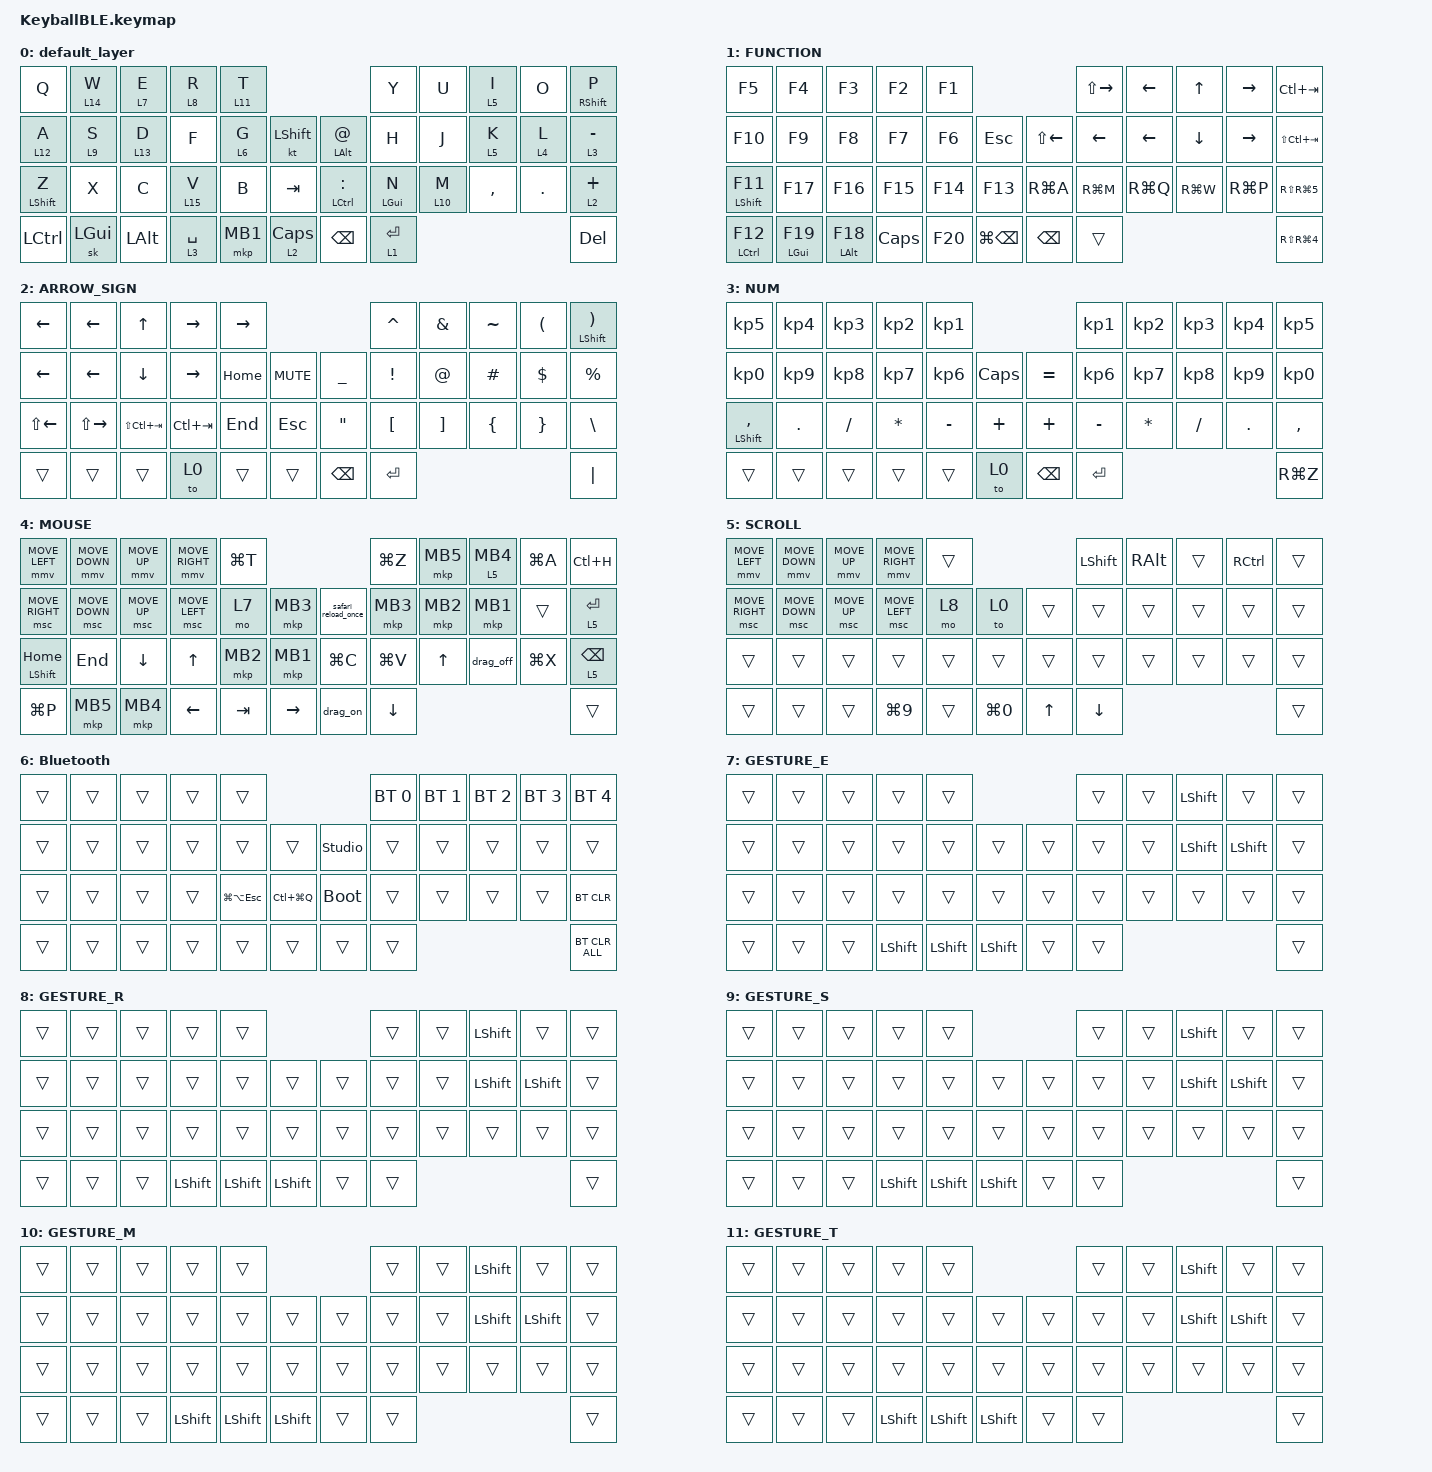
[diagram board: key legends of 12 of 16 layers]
/* ===============================
 * KeyballBLE.keymap（全置き換え / 整理版）
 *  - レイヤー順＝番号（0起算）
 *    0 default_layer
 *    1 FUNCTION
 *    2 ARROW_SIGN
 *    3 NUM
 *    4 MOUSE
 *    5 SCROLL
 *    6 Bluetooth
 *    7 GESTURE_E
 *    8 GESTURE_R
 *    9 GESTURE_S
 *   10 GESTURE_M
 *   11 GESTURE_T
 *   12 GESTURE_A
 *   13 GESTURE_D
 *   14 GESTURE_W
 *   15 SCROLL_SNAP
 *   16 SNIPE（キーで遅いスクロール：MOVE_X/Y(8)）
 *  - overlay 側で gesture を 7/8/9/10/11/12/13/14 に紐付け
 *  - mm_l*_dir は overlay の zip_mouse_gesture_* から呼ばれる
 * =============================== */

#define ZMK_POINTING_DEFAULT_SCRL_VAL 80

#include "dts/mouse-gesture.local.dtsi"
#include <dt-bindings/zmk/mouse.h>
#include <behaviors.dtsi>
#include <dt-bindings/zmk/bt.h>
#include <dt-bindings/zmk/keys.h>
#include <dt-bindings/zmk/pointing.h>

&msc {
    time-to-max-speed-ms = <0>;
    acceleration-exponent = <0>;
};

&mt {
    flavor = "balanced";
    quick-tap-ms = <0>;
};

&mouse_gesture_kp {
    tapping-term-ms = <200>;
    quick-tap-ms = <0>;
    flavor = "tap-preferred";
};

&mouse_gesture_mkp {
    tapping-term-ms = <200>;
    quick-tap-ms = <0>;
    flavor = "tap-preferred";
};

/ {
    combos {
        compatible = "zmk,combos";

        mb2_combo {
            bindings = <&mkp MB2>;
            key-positions = <19 18>;
        };

        scroll_combos {
            bindings = <&tog 5>;
            key-positions = <7 8>;
        };

        drag_off_combo {
            bindings = <&drag_off>;
            key-positions = <31 32>;
        };

        key1 {
            bindings = <&kp EXCLAMATION>;
            key-positions = <17 18>;
        };

        key2 {
            bindings = <&kp QUESTION>;
            key-positions = <29 30>;
        };

        scrl_up {
            bindings = <&msc MOVE_UP>;
            key-positions = <21 33>;
        };

        scrl_down {
            bindings = <&msc MOVE_DOWN>;
            key-positions = <33 42>;
        };

        left_shift {
            bindings = <&kp LEFT_SHIFT>;
            key-positions = <0 1>;
        };

        right_shift {
            bindings = <&kp LEFT_SHIFT>;
            key-positions = <8 9>;
        };

        tab {
            bindings = <&kp TAB>;
            key-positions = <11 12>;
        };

        lstab {
            bindings = <&kp LS(TAB)>;
            key-positions = <1 2>;
        };

        click {
            bindings = <&mkp MB1>;
            key-positions = <19 20>;
        };
    };

    macros {
        safari_reload_once: safari_reload_once {
            compatible = "zmk,behavior-macro";
            label = "SAFARI_RELOAD_ONCE";
            #binding-cells = <0>;
            bindings =
                <&macro_press>,
                <&kp LGUI>,
                <&macro_tap>,
                <&kp R>,
                <&macro_release>,
                <&kp LGUI>;
        };

        to_layer_0: to_layer_0 {
            compatible = "zmk,behavior-macro-one-param";
            label = "TO_LAYER_0";
            #binding-cells = <1>;
            bindings = <&to 0 &macro_param_1to1 &kp MACRO_PLACEHOLDER>;
        };

        drag_on: drag_on {
            compatible = "zmk,behavior-macro";
            label = "DRAG_ON";
            #binding-cells = <0>;
            bindings = <&macro_press>, <&mkp MB1>;
        };

        drag_off: drag_off {
            compatible = "zmk,behavior-macro";
            label = "DRAG_OFF";
            #binding-cells = <0>;
            bindings = <&macro_release>, <&mkp MB1>;
        };

        lm: lm {
            compatible = "zmk,behavior-macro-two-param";
            #binding-cells = <2>;
            wait-ms = <0>;
            tap-ms = <0>;
            bindings =
                <&macro_param_1to1>,
                <&macro_press>,
                <&mo MACRO_PLACEHOLDER &macro_param_2to1>,
                <&macro_press>,
                <&kp MACRO_PLACEHOLDER>,
                <&macro_pause_for_release>,
                <&macro_param_2to1>,
                <&macro_release>,
                <&kp MACRO_PLACEHOLDER &macro_param_1to1>,
                <&macro_release>,
                <&mo MACRO_PLACEHOLDER>;
        };
    };

    behaviors {
        gesture_mo_kp: gesture_mo_kp {
            compatible = "zmk,behavior-hold-tap";
            label = "GESTURE_MO_KP";
            bindings = <&mo>, <&kp>;

            #binding-cells = <2>;

            /* タップ優先（キー入力寄り） */

            flavor = "tap-preferred";
            tapping-term-ms = <210>;
            quick-tap-ms = <150>;
            require-prior-idle-ms = <450>;
        };

        lt_to_layer_0: lt_to_layer_0 {
            compatible = "zmk,behavior-hold-tap";
            label = "LAYER_TAP_TO_0";
            bindings = <&mo>, <&to_layer_0>;

            #binding-cells = <2>;
            tapping-term-ms = <210>;
            flavor = "tap-preferred";
            quick-tap-ms = <150>;
            require-prior-idle-ms = <350>;
        };

        rotate: rotate {
            compatible = "zmk,behavior-sensor-rotate";
            label = "ROTATE";
            #sensor-binding-cells = <0>;
            bindings = <&msc MOVE_UP>, <&msc MOVE_DOWN>;

            tap-ms = <20>;
        };

        lt_mkp: lt_mkp {
            compatible = "zmk,behavior-hold-tap";
            label = "LT_MKP";
            bindings = <&mo>, <&mkp>;

            #binding-cells = <2>;
            tapping-term-ms = <200>;
        };

        mod_mkp: mod_mkp {
            compatible = "zmk,behavior-hold-tap";
            label = "MOD_MKP";
            bindings = <&kp>, <&mkp>;

            #binding-cells = <2>;
            tapping-term-ms = <200>;
        };

        dragkey: dragkey {
            compatible = "zmk,behavior-hold-tap";
            label = "DRAGKEY";
            bindings = <&drag_on>, <&mkp>;

            #binding-cells = <2>;
            tapping-term-ms = <200>;
            require-prior-idle-ms = <150>;
            flavor = "tap-preferred";
            quick-tap-ms = <100>;
        };

        g_shft: g_shft {
            compatible = "zmk,behavior-sticky-key";
            #binding-cells = <1>;
            release-after-ms = <1000>;
            bindings = <&kp>;
        };

        mm_l1_up: mm_l1_up {
            compatible = "zmk,behavior-mod-morph";
            #binding-cells = <0>;
            mods = <(MOD_LSFT|MOD_RSFT)>;
            bindings = <&kp LC(B)>, <&kp LC(LA(LG(NUMBER_1)))>;
        };

        mm_l1_down: mm_l1_down {
            compatible = "zmk,behavior-mod-morph";
            #binding-cells = <0>;
            mods = <(MOD_LSFT|MOD_RSFT)>;
            bindings = <&kp LG(SPACE)>, <&kp LC(LA(LG(NUMBER_4)))>;
        };

        mm_l1_left: mm_l1_left {
            compatible = "zmk,behavior-mod-morph";
            #binding-cells = <0>;
            mods = <(MOD_LSFT|MOD_RSFT)>;
            bindings = <&kp LG(LS(TAB))>, <&kp LC(LA(LG(NUMBER_3)))>;
        };

        mm_l1_right: mm_l1_right {
            compatible = "zmk,behavior-mod-morph";
            #binding-cells = <0>;
            mods = <(MOD_LSFT|MOD_RSFT)>;
            bindings = <&kp LG(TAB)>, <&kp LC(LA(LG(NUMBER_2)))>;
        };

        mm_l2_up: mm_l2_up {
            compatible = "zmk,behavior-mod-morph";
            #binding-cells = <0>;
            mods = <(MOD_LSFT|MOD_RSFT)>;
            bindings = <&kp LC(UP_ARROW)>, <&kp F12>;
        };

        mm_l2_down: mm_l2_down {
            compatible = "zmk,behavior-mod-morph";
            #binding-cells = <0>;
            mods = <(MOD_LSFT|MOD_RSFT)>;
            bindings = <&kp LG(H)>, <&kp F16>;
        };

        mm_l2_left: mm_l2_left {
            compatible = "zmk,behavior-mod-morph";
            #binding-cells = <0>;
            mods = <(MOD_LSFT|MOD_RSFT)>;
            bindings = <&kp F15>, <&kp F11>;
        };

        mm_l2_right: mm_l2_right {
            compatible = "zmk,behavior-mod-morph";
            #binding-cells = <0>;
            mods = <(MOD_LSFT|MOD_RSFT)>;
            bindings = <&kp F14>, <&kp F20>;
        };

        mm_l3_up: mm_l3_up {
            compatible = "zmk,behavior-mod-morph";
            #binding-cells = <0>;
            mods = <(MOD_LSFT|MOD_RSFT)>;
            bindings = <&kp F3>, <&kp HOME>;
        };

        mm_l3_down: mm_l3_down {
            compatible = "zmk,behavior-mod-morph";
            #binding-cells = <0>;
            mods = <(MOD_LSFT|MOD_RSFT)>;
            bindings = <&kp LG(M)>, <&kp END>;
        };

        mm_l3_left: mm_l3_left {
            compatible = "zmk,behavior-mod-morph";
            #binding-cells = <0>;
            mods = <(MOD_LSFT|MOD_RSFT)>;
            bindings = <&mkp MB4>, <&kp LG(Q)>;
        };

        mm_l3_right: mm_l3_right {
            compatible = "zmk,behavior-mod-morph";
            #binding-cells = <0>;
            mods = <(MOD_LSFT|MOD_RSFT)>;
            bindings = <&mkp MB5>, <&kp LG(W)>;
        };

        mm_l7_up: mm_l7_up {
            compatible = "zmk,behavior-mod-morph";
            #binding-cells = <0>;
            mods = <(MOD_LSFT|MOD_RSFT)>;
            bindings = <&kp LG(T)>, <&kp LG(R)>;
        };

        mm_l7_down: mm_l7_down {
            compatible = "zmk,behavior-mod-morph";
            #binding-cells = <0>;
            mods = <(MOD_LSFT|MOD_RSFT)>;
            bindings = <&kp LG(W)>, <&kp LG(F)>;
        };

        mm_l7_left: mm_l7_left {
            compatible = "zmk,behavior-mod-morph";
            #binding-cells = <0>;
            mods = <(MOD_LSFT|MOD_RSFT)>;
            bindings = <&kp LC(LS(TAB))>, <&kp LG(MINUS)>;
        };

        mm_l7_right: mm_l7_right {
            compatible = "zmk,behavior-mod-morph";
            #binding-cells = <0>;
            mods = <(MOD_LSFT|MOD_RSFT)>;
            bindings = <&kp LC(TAB)>, <&kp LG(PLUS)>;
        };

        mm_l11_up: mm_l11_up {
            compatible = "zmk,behavior-mod-morph";
            #binding-cells = <0>;
            mods = <(MOD_LSFT|MOD_RSFT)>;
            bindings = <&kp LG(C)>, <&kp LG(X)>;
        };

        mm_l11_down: mm_l11_down {
            compatible = "zmk,behavior-mod-morph";
            #binding-cells = <0>;
            mods = <(MOD_LSFT|MOD_RSFT)>;
            bindings = <&kp LG(V)>, <&kp LG(V)>;
        };

        mm_l11_left: mm_l11_left {
            compatible = "zmk,behavior-mod-morph";
            #binding-cells = <0>;
            mods = <(MOD_LSFT|MOD_RSFT)>;
            bindings = <&kp LG(Z)>, <&kp LG(P)>;
        };

        mm_l11_right: mm_l11_right {
            compatible = "zmk,behavior-mod-morph";
            #binding-cells = <0>;
            mods = <(MOD_LSFT|MOD_RSFT)>;
            bindings = <&kp LG(LS(Z))>, <&kp LG(RET)>;
        };

        mm_l12_up: mm_l12_up {
            compatible = "zmk,behavior-mod-morph";
            #binding-cells = <0>;
            mods = <(MOD_LSFT|MOD_RSFT)>;
            bindings = <&kp LG(A)>, <&kp LG(LS(UP_ARROW))>;
        };

        mm_l12_down: mm_l12_down {
            compatible = "zmk,behavior-mod-morph";
            #binding-cells = <0>;
            mods = <(MOD_LSFT|MOD_RSFT)>;
            bindings = <&kp LG(X)>, <&kp LG(LS(DOWN_ARROW))>;
        };

        mm_l12_left: mm_l12_left {
            compatible = "zmk,behavior-mod-morph";
            #binding-cells = <0>;
            mods = <(MOD_LSFT|MOD_RSFT)>;
            bindings = <&kp LA(LS(LEFT_ARROW))>, <&kp LG(LS(LEFT_ARROW))>;
        };

        mm_l12_right: mm_l12_right {
            compatible = "zmk,behavior-mod-morph";
            #binding-cells = <0>;
            mods = <(MOD_LSFT|MOD_RSFT)>;
            bindings = <&kp LA(LS(RIGHT_ARROW))>, <&kp LG(LS(RIGHT_ARROW))>;
        };

        mm_l13_up: mm_l13_up {
            compatible = "zmk,behavior-mod-morph";
            #binding-cells = <0>;
            mods = <(MOD_LSFT|MOD_RSFT)>;
            bindings = <&kp LG(LS(NUMBER_3))>, <&kp LC(LG(LS(NUMBER_3)))>;
        };

        mm_l13_down: mm_l13_down {
            compatible = "zmk,behavior-mod-morph";
            #binding-cells = <0>;
            mods = <(MOD_LSFT|MOD_RSFT)>;
            bindings = <&kp ESC>, <&kp ESC>;
        };

        mm_l13_left: mm_l13_left {
            compatible = "zmk,behavior-mod-morph";
            #binding-cells = <0>;
            mods = <(MOD_LSFT|MOD_RSFT)>;
            bindings = <&kp LG(LS(NUMBER_4))>, <&kp LC(LG(LS(NUMBER_4)))>;
        };

        mm_l13_right: mm_l13_right {
            compatible = "zmk,behavior-mod-morph";
            #binding-cells = <0>;
            mods = <(MOD_LSFT|MOD_RSFT)>;
            bindings = <&kp LG(LS(NUMBER_5))>, <&kp LG(LS(NUMBER_5))>;
        };

        mm_l14_up: mm_l14_up {
            compatible = "zmk,behavior-mod-morph";
            #binding-cells = <0>;
            mods = <(MOD_LSFT|MOD_RSFT)>;
            bindings = <&kp C_VOLUME_UP>, <&kp F13>;
        };

        mm_l14_down: mm_l14_down {
            compatible = "zmk,behavior-mod-morph";
            #binding-cells = <0>;
            mods = <(MOD_LSFT|MOD_RSFT)>;
            bindings = <&kp C_VOLUME_DOWN>, <&kp C_MUTE>;
        };

        mm_l14_left: mm_l14_left {
            compatible = "zmk,behavior-mod-morph";
            #binding-cells = <0>;
            mods = <(MOD_LSFT|MOD_RSFT)>;
            bindings = <&kp C_BRI_DN>, <&kp F19>;
        };

        mm_l14_right: mm_l14_right {
            compatible = "zmk,behavior-mod-morph";
            #binding-cells = <0>;
            mods = <(MOD_LSFT|MOD_RSFT)>;
            bindings = <&kp C_BRI_UP>, <&kp F18>;
        };
    };

    keymap {
        compatible = "zmk,keymap";

        default_layer {
            bindings = <
&kp Q                &gesture_mo_kp 14 W  &gesture_mo_kp 7 E   &gesture_mo_kp 8 R   &gesture_mo_kp 11 T                                              &kp Y           &kp U                &gesture_mo_kp 5 I  &kp O       &mt RIGHT_SHIFT P
&gesture_mo_kp 12 A  &gesture_mo_kp 9 S   &gesture_mo_kp 13 D  &kp F                &lt 6 G              &kt LEFT_SHIFT      &mt LEFT_ALT AT_SIGN    &kp H           &kp J                &gesture_mo_kp 5 K  &lt 4 L     &lt 3 MINUS
&mt LEFT_SHIFT Z     &kp X                &kp C                &gesture_mo_kp 15 V  &kp B                &kp TAB             &mt LEFT_CONTROL COLON  &mt LEFT_GUI N  &gesture_mo_kp 10 M  &kp COMMA           &kp PERIOD  &lt 2 PLUS
&kp LCTRL            &sk LEFT_GUI         &kp LEFT_ALT         &lt 3 SPACE          &mkp MB1             &lt 2 CAPS          &kp BACKSPACE           &lt 1 ENTER                                                          &kp DELETE
            >;

            sensor-bindings = <&inc_dec_kp DOWN_ARROW UP_ARROW>;
        };

        FUNCTION {
            bindings = <
&kp F5                &kp F4            &kp F3            &kp F2    &kp F1                                              &kp LS(RIGHT_ARROW)  &kp LEFT_ARROW  &kp UP_ARROW    &kp RIGHT_ARROW  &kp LC(TAB)
&kp F10               &kp F9            &kp F8            &kp F7    &kp F6   &kp ESC                &kp LS(LEFT_ARROW)  &kp LEFT_ARROW       &kp LEFT_ARROW  &kp DOWN_ARROW  &kp RIGHT_ARROW  &kp LS(LC(TAB))
&mt LEFT_SHIFT F11    &kp F17           &kp F16           &kp F15   &kp F14  &kp F13                &kp RG(A)           &kp RG(M)            &kp RG(Q)       &kp RG(W)       &kp RG(P)        &kp RS(RG(NUMBER_5))
&mt LEFT_CONTROL F12  &mt LEFT_GUI F19  &mt LEFT_ALT F18  &kp CAPS  &kp F20  &kp LG(BACKSPACE)      &kp BACKSPACE       &trans                                                                &kp RS(RG(NUMBER_4))
            >;

            sensor-bindings = <&inc_dec_kp RIGHT_ARROW LEFT_ARROW>;
        };

        ARROW_SIGN {
            bindings = <
&kp LEFT_ARROW      &kp LEFT_ARROW       &kp UP_ARROW     &kp RIGHT_ARROW  &kp RIGHT_ARROW                                     &kp CARET         &kp AMPERSAND      &kp TILDE       &kp LEFT_PARENTHESIS  &mt LEFT_SHIFT RIGHT_PARENTHESIS
&kp LEFT_ARROW      &kp LEFT_ARROW       &kp DOWN_ARROW   &kp RIGHT_ARROW  &kp HOME         &kp C_MUTE      &kp UNDERSCORE     &kp EXCLAMATION   &kp AT_SIGN        &kp HASH        &kp DOLLAR            &kp PERCENT
&kp LS(LEFT_ARROW)  &kp LS(RIGHT_ARROW)  &kp LS(LC(TAB))  &kp LC(TAB)      &kp END          &kp ESC         &kp DOUBLE_QUOTES  &kp LEFT_BRACKET  &kp RIGHT_BRACKET  &kp LEFT_BRACE  &kp RIGHT_BRACE       &kp BACKSLASH
&trans              &trans               &trans           &to 0            &trans           &trans          &kp BACKSPACE      &kp ENTER                                                                  &kp PIPE
            >;

            sensor-bindings = <&inc_dec_kp C_VOLUME_DOWN C_VOLUME_UP>;
        };

        NUM {
            bindings = <
&kp KP_NUMBER_5       &kp KP_NUMBER_4  &kp KP_NUMBER_3  &kp KP_NUMBER_2  &kp KP_NUMBER_1                               &kp KP_NUMBER_1  &kp KP_NUMBER_2  &kp KP_NUMBER_3  &kp KP_NUMBER_4  &kp KP_NUMBER_5
&kp KP_NUMBER_0       &kp KP_NUMBER_9  &kp KP_NUMBER_8  &kp KP_NUMBER_7  &kp KP_NUMBER_6  &kp CAPS      &kp EQUAL      &kp KP_NUMBER_6  &kp KP_NUMBER_7  &kp KP_NUMBER_8  &kp KP_NUMBER_9  &kp KP_NUMBER_0
&mt LEFT_SHIFT COMMA  &kp PERIOD       &kp SLASH        &kp ASTERISK     &kp MINUS        &kp PLUS      &kp PLUS       &kp MINUS        &kp ASTERISK     &kp SLASH        &kp PERIOD       &kp COMMA
&trans                &trans           &trans           &trans           &trans           &to 0         &kp BACKSPACE  &kp ENTER                                                           &kp RG(Z)
            >;

            sensor-bindings = <&inc_dec_kp C_BRI_DN C_BRI_UP>;
        };

        MOUSE {
            bindings = <
&mmv MOVE_LEFT       &mmv MOVE_DOWN  &mmv MOVE_UP    &mmv MOVE_RIGHT  &kp LG(T)                                            &kp LG(Z)       &mkp MB5      &lt_mkp 5 MB4  &kp LG(A)  &kp LC(H)
&msc MOVE_RIGHT      &msc MOVE_DOWN  &msc MOVE_UP    &msc MOVE_LEFT   &mo 7      &mkp MB3             &safari_reload_once  &mkp MB3        &mkp MB2      &mkp MB1       &trans     &lt 5 ENTER
&mt LEFT_SHIFT HOME  &kp END         &kp DOWN_ARROW  &kp UP_ARROW     &mkp MB2   &mkp MB1             &kp LG(C)            &kp LG(V)       &kp UP_ARROW  &drag_off      &kp LG(X)  &lt 5 BACKSPACE
&kp LG(P)            &mkp MB5        &mkp MB4        &kp LEFT_ARROW   &kp TAB    &kp RIGHT_ARROW      &drag_on             &kp DOWN_ARROW                                          &trans
            >;

            sensor-bindings = <&rotate>;
        };

        SCROLL {
            bindings = <
&mmv MOVE_LEFT   &mmv MOVE_DOWN  &mmv MOVE_UP  &mmv MOVE_RIGHT   &trans                                      &kp LEFT_SHIFT  &kp RIGHT_ALT  &trans  &kp RIGHT_CONTROL  &trans
&msc MOVE_RIGHT  &msc MOVE_DOWN  &msc MOVE_UP  &msc MOVE_LEFT    &mo 8   &to 0                 &trans        &trans          &trans         &trans  &trans             &trans
&trans           &trans          &trans        &trans            &trans  &trans                &trans        &trans          &trans         &trans  &trans             &trans
&trans           &trans          &trans        &kp LG(NUMBER_9)  &trans  &kp LG(NUMBER_0)      &kp UP_ARROW  &kp DOWN_ARROW                                            &trans
            >;

            sensor-bindings = <&inc_dec_kp LG(LA(MINUS)) LG(LA(PLUS))>;
        };

        Bluetooth {
            bindings = <
&trans  &trans  &trans  &trans  &trans                                              &bt BT_SEL 0  &bt BT_SEL 1  &bt BT_SEL 2  &bt BT_SEL 3  &bt BT_SEL 4
&trans  &trans  &trans  &trans  &trans           &trans             &studio_unlock  &trans        &trans        &trans        &trans        &trans
&trans  &trans  &trans  &trans  &kp LG(LA(ESC))  &kp LC(LG(Q))      &bootloader     &trans        &trans        &trans        &trans        &bt BT_CLR
&trans  &trans  &trans  &trans  &trans           &trans             &trans          &trans                                                  &bt BT_CLR_ALL
            >;

            sensor-bindings = <&rotate>;
        };

        GESTURE_E {
            bindings = <
&trans  &trans  &trans  &trans          &trans                                      &trans  &trans  &kp LEFT_SHIFT  &trans          &trans
&trans  &trans  &trans  &trans          &trans          &trans              &trans  &trans  &trans  &kp LEFT_SHIFT  &kp LEFT_SHIFT  &trans
&trans  &trans  &trans  &trans          &trans          &trans              &trans  &trans  &trans  &trans          &trans          &trans
&trans  &trans  &trans  &kp LEFT_SHIFT  &kp LEFT_SHIFT  &kp LEFT_SHIFT      &trans  &trans                                          &trans
            >;

            sensor-bindings = <&inc_dec_kp F15 F14>;
        };

        GESTURE_R {
            bindings = <
&trans  &trans  &trans  &trans          &trans                                      &trans  &trans  &kp LEFT_SHIFT  &trans          &trans
&trans  &trans  &trans  &trans          &trans          &trans              &trans  &trans  &trans  &kp LEFT_SHIFT  &kp LEFT_SHIFT  &trans
&trans  &trans  &trans  &trans          &trans          &trans              &trans  &trans  &trans  &trans          &trans          &trans
&trans  &trans  &trans  &kp LEFT_SHIFT  &kp LEFT_SHIFT  &kp LEFT_SHIFT      &trans  &trans                                          &trans
            >;

            sensor-bindings = <&inc_dec_kp LG(MINUS) LG(PLUS)>;
        };

        GESTURE_S {
            bindings = <
&trans  &trans  &trans  &trans          &trans                                      &trans  &trans  &kp LEFT_SHIFT  &trans          &trans
&trans  &trans  &trans  &trans          &trans          &trans              &trans  &trans  &trans  &kp LEFT_SHIFT  &kp LEFT_SHIFT  &trans
&trans  &trans  &trans  &trans          &trans          &trans              &trans  &trans  &trans  &trans          &trans          &trans
&trans  &trans  &trans  &kp LEFT_SHIFT  &kp LEFT_SHIFT  &kp LEFT_SHIFT      &trans  &trans                                          &trans
            >;
        };

        GESTURE_M {
            bindings = <
&trans  &trans  &trans  &trans          &trans                                      &trans  &trans  &kp LEFT_SHIFT  &trans          &trans
&trans  &trans  &trans  &trans          &trans          &trans              &trans  &trans  &trans  &kp LEFT_SHIFT  &kp LEFT_SHIFT  &trans
&trans  &trans  &trans  &trans          &trans          &trans              &trans  &trans  &trans  &trans          &trans          &trans
&trans  &trans  &trans  &kp LEFT_SHIFT  &kp LEFT_SHIFT  &kp LEFT_SHIFT      &trans  &trans                                          &trans
            >;
        };

        GESTURE_T {
            bindings = <
&trans  &trans  &trans  &trans          &trans                                      &trans  &trans  &kp LEFT_SHIFT  &trans          &trans
&trans  &trans  &trans  &trans          &trans          &trans              &trans  &trans  &trans  &kp LEFT_SHIFT  &kp LEFT_SHIFT  &trans
&trans  &trans  &trans  &trans          &trans          &trans              &trans  &trans  &trans  &trans          &trans          &trans
&trans  &trans  &trans  &kp LEFT_SHIFT  &kp LEFT_SHIFT  &kp LEFT_SHIFT      &trans  &trans                                          &trans
            >;
        };

        GESTURE_A {
            bindings = <
&trans  &trans  &trans  &trans          &trans                                      &trans  &trans  &kp LEFT_SHIFT  &trans          &trans
&trans  &trans  &trans  &trans          &trans          &trans              &trans  &trans  &trans  &kp LEFT_SHIFT  &kp LEFT_SHIFT  &trans
&trans  &trans  &trans  &trans          &trans          &trans              &trans  &trans  &trans  &trans          &trans          &trans
&trans  &trans  &trans  &kp LEFT_SHIFT  &kp LEFT_SHIFT  &kp LEFT_SHIFT      &trans  &trans                                          &trans
            >;
        };

        GESTURE_D {
            bindings = <
&trans  &trans  &trans  &trans          &trans                                      &trans  &trans  &kp LEFT_SHIFT  &trans          &trans
&trans  &trans  &trans  &trans          &trans          &trans              &trans  &trans  &trans  &kp LEFT_SHIFT  &kp LEFT_SHIFT  &trans
&trans  &trans  &trans  &trans          &trans          &trans              &trans  &trans  &trans  &trans          &trans          &trans
&trans  &trans  &trans  &kp LEFT_SHIFT  &kp LEFT_SHIFT  &kp LEFT_SHIFT      &trans  &trans                                          &trans
            >;
        };

        GESTURE_W {
            bindings = <
&trans  &trans  &trans  &trans          &trans                                      &trans  &trans  &kp LEFT_SHIFT  &trans          &trans
&trans  &trans  &trans  &trans          &trans          &trans              &trans  &trans  &trans  &kp LEFT_SHIFT  &kp LEFT_SHIFT  &trans
&trans  &trans  &trans  &trans          &trans          &trans              &trans  &trans  &trans  &trans          &trans          &trans
&trans  &trans  &trans  &kp LEFT_SHIFT  &kp LEFT_SHIFT  &kp LEFT_SHIFT      &trans  &trans                                          &trans
            >;
        };

        /* layer16：キーで遅いスクロール（縦＋横） */

        SNIPE {
            bindings = <
&trans  &trans           &trans           &trans          &trans                      &trans           &trans           &trans          &trans          &trans
&trans  &trans           &msc MOVE_Y(8)   &trans          &trans  &trans      &trans  &msc MOVE_X(-8)  &msc MOVE_Y(-8)  &msc MOVE_Y(8)  &msc MOVE_X(8)  &trans
&trans  &msc MOVE_X(-8)  &msc MOVE_Y(-8)  &msc MOVE_X(8)  &trans  &trans      &trans  &trans           &trans           &trans          &trans          &trans
&trans  &trans           &trans           &trans          &trans  &trans      &trans  &trans                                                            &trans
            >;
        };
    };
};
